# ESP32-S3 register map
Vendor: ESPRESSIF SYSTEMS (SHANGHAI) CO., LTD.; Series: ESP32 S-Series; File version: 22
CPU: Xtensa LX7 r0p0, little endian, no MPU, FPU, 0 interrupt priority bits
Address unit: 32 bits
Registers are 32-bit, read-write, reset 0x0 unless marked. A register's access mark holds for its fields unless they carry their own. Offsets are from the block's base; [hi:lo] are bit positions; {n}, {i} and the like mark numbered series.

## APB_SARADC — SAR (Successive Approximation Register) Analog-to-Digital Converter
Base 0x60040000
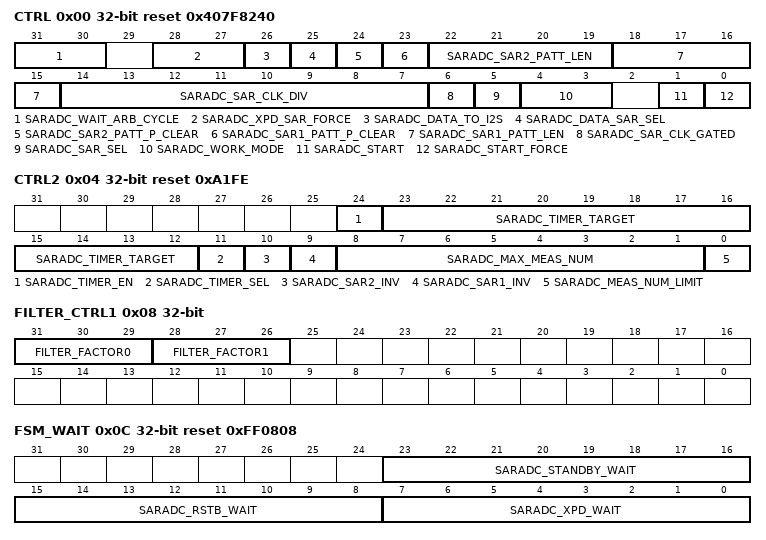
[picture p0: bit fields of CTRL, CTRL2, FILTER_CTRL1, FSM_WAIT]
0x00 CTRL reset 0x407F8240 — configure apb saradc controller
  [31:30] SARADC_WAIT_ARB_CYCLE — wait arbit signal stable after sar_done
  [28:27] SARADC_XPD_SAR_FORCE — force option to xpd sar blocks
  [26] SARADC_DATA_TO_I2S — 1: I2S input data is from SAR ADC (for DMA), 0: I2S input data is from GPIO matrix
  [25] SARADC_DATA_SAR_SEL — 1: sar_sel will be coded by the MSB of the 16-bit output data, in this case the resolution should not be larger than 11 bits.
  [24] SARADC_SAR2_PATT_P_CLEAR — clear the pointer of pattern table for DIG ADC2 CTRL
  [23] SARADC_SAR1_PATT_P_CLEAR — clear the pointer of pattern table for DIG ADC1 CTRL
  [22:19] SARADC_SAR2_PATT_LEN — 0 ~ 15 means length 1 ~ 16
  [18:15] SARADC_SAR1_PATT_LEN — 0 ~ 15 means length 1 ~ 16
  [14:7] SARADC_SAR_CLK_DIV — SAR clock divider
  [6] SARADC_SAR_CLK_GATED — enable SAR CLK gate when saradc idle
  [5] SARADC_SAR_SEL — 0: SAR1, 1: SAR2, only work for single SAR mode
  [4:3] SARADC_WORK_MODE — 0: single mode, 1: double mode, 2: alternate mode
  [1] SARADC_START — start saradc by sw
  [0] SARADC_START_FORCE — enable start saradc by sw
0x04 CTRL2 reset 0xA1FE — configure apb saradc controller
  [24] SARADC_TIMER_EN — to enable saradc timer trigger
  [23:12] SARADC_TIMER_TARGET — to set saradc timer target
  [11] SARADC_TIMER_SEL — 1: select saradc timer 0: i2s_ws trigger
  [10] SARADC_SAR2_INV — 1: data to DIG ADC2 CTRL is inverted, otherwise not
  [9] SARADC_SAR1_INV — 1: data to DIG ADC1 CTRL is inverted, otherwise not
  [8:1] SARADC_MAX_MEAS_NUM — max conversion number
  [0] SARADC_MEAS_NUM_LIMIT — enable apb saradc limit the sample num
0x08 FILTER_CTRL1 — configure saradc filter
  [31:29] FILTER_FACTOR0 — apb saradc factor0
  [28:26] FILTER_FACTOR1 — apb saradc factor1
0x0C FSM_WAIT reset 0xFF0808 — configure apb saradc fsm
  [23:16] SARADC_STANDBY_WAIT — the cycle which saradc controller in standby state
  [15:8] SARADC_RSTB_WAIT — the cycle which saradc controller in rst state
  [7:0] SARADC_XPD_WAIT — the cycle which saradc controller in xpd state
0x10 SAR1_STATUS ro — saradc1 status for debug
  [31:0] SARADC_SAR1_STATUS — saradc1 status
0x14 SAR2_STATUS ro — saradc2 status for debug
  [31:0] SARADC_SAR2_STATUS — saradc2 status
0x18 SAR1_PATT_TAB1 — configure apb saradc pattern table
  [23:0] SARADC_SAR1_PATT_TAB1 — item 0 ~ 3 for pattern table 1 (each item 6bit)
{0x14+4i} SAR1_PATT_TAB{i} (i=2..4) — configure apb saradc pattern table
  [23:0] SARADC_SAR1_PATT_TAB{i} — Item {4i-4} ~ {4i-1} for pattern table 1 (each item 6bit)
0x28 SAR2_PATT_TAB1 — configure apb saradc pattern table
  [23:0] SARADC_SAR2_PATT_TAB1 — item 0 ~ 3 for pattern table 2 (each item 6bit)
{0x24+4i} SAR2_PATT_TAB{i} (i=2..4) — configure apb saradc pattern table
  [23:0] SARADC_SAR2_PATT_TAB{i} — Item {4i-4} ~ {4i-1} for pattern table 2 (each item 6bit)
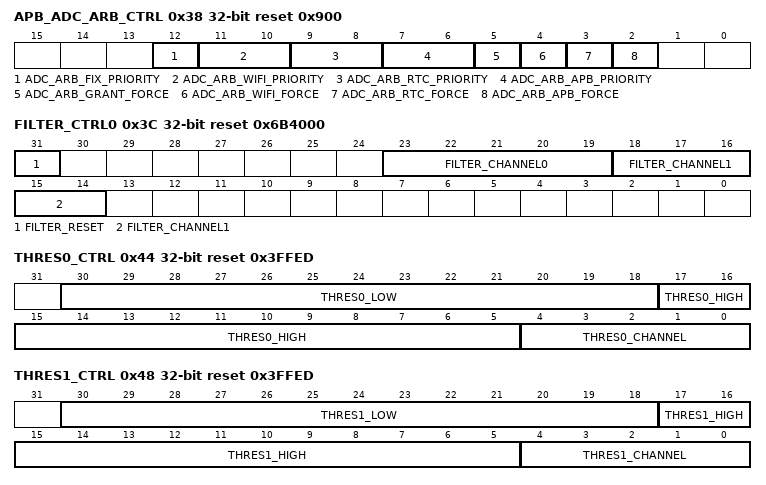
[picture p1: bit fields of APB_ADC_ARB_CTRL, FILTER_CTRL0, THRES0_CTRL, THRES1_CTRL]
0x38 APB_ADC_ARB_CTRL reset 0x900 — configure apb saradc arbit
  [12] ADC_ARB_FIX_PRIORITY — adc2 arbiter uses fixed priority
  [11:10] ADC_ARB_WIFI_PRIORITY — Set adc2 arbiter wifi priority
  [9:8] ADC_ARB_RTC_PRIORITY — Set adc2 arbiter rtc priority
  [7:6] ADC_ARB_APB_PRIORITY — Set adc2 arbiterapb priority
  [5] ADC_ARB_GRANT_FORCE — adc2 arbiter force grant
  [4] ADC_ARB_WIFI_FORCE — adc2 arbiter force to enable wifi controller
  [3] ADC_ARB_RTC_FORCE — adc2 arbiter force to enable rtc controller
  [2] ADC_ARB_APB_FORCE — adc2 arbiter force to enableapb controller
0x3C FILTER_CTRL0 reset 0x6B4000 — configure apb saradc arbit
  [31] FILTER_RESET — enable apb_adc1_filter
  [23:19] FILTER_CHANNEL0 — configure the filter0 channel
  [18:14] FILTER_CHANNEL1 — configure the filter1 channel
0x40 APB_SARADC1_DATA_STATUS ro — get apb saradc sample data
  [16:0] APB_SARADC1_DATA — apbsaradc sample data
0x44 THRES0_CTRL reset 0x3FFED — configure apb saradc thres monitor
  [30:18] THRES0_LOW — thres0 monitor low thres
  [17:5] THRES0_HIGH — thres0 monitor high thres
  [4:0] THRES0_CHANNEL — configure which channel thres0 monitor
0x48 THRES1_CTRL reset 0x3FFED — configure apb saradc thres monitor
  [30:18] THRES1_LOW — thres1 monitor low thres
  [17:5] THRES1_HIGH — thres1 monitor high thres
  [4:0] THRES1_CHANNEL — configure which channel thres0 monitor
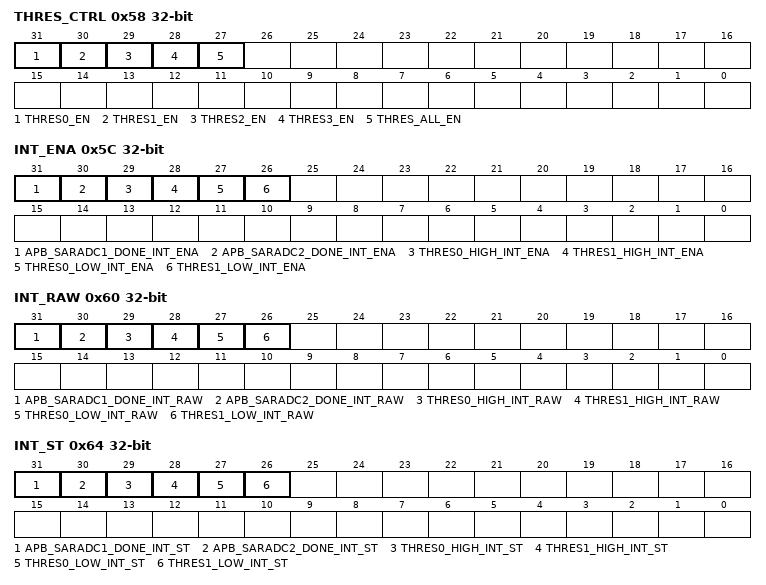
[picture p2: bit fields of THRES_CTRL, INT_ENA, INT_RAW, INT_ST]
0x58 THRES_CTRL — configure thres monitor enable
  [31] THRES0_EN — enable thres0
  [30] THRES1_EN — enable thres1
  [29] THRES2_EN — no public
  [28] THRES3_EN — no public
  [27] THRES_ALL_EN — enable thres0 to monitor all channel
0x5C INT_ENA — enable interrupt
  [31] APB_SARADC1_DONE_INT_ENA — interrupt of sar1 done
  [30] APB_SARADC2_DONE_INT_ENA — interrupt of sar2 done
  [29] THRES0_HIGH_INT_ENA — interrupt of thres0 high
  [28] THRES1_HIGH_INT_ENA — interrupt of thres1 high
  [27] THRES0_LOW_INT_ENA — interrupt of thres0 low
  [26] THRES1_LOW_INT_ENA — interrupt of thres1 low
0x60 INT_RAW ro — raw of interrupt
  [31] APB_SARADC1_DONE_INT_RAW — interrupt of sar1 done
  [30] APB_SARADC2_DONE_INT_RAW — interrupt of sar2 done
  [29] THRES0_HIGH_INT_RAW — interrupt of thres0 high
  [28] THRES1_HIGH_INT_RAW — interrupt of thres1 high
  [27] THRES0_LOW_INT_RAW — interrupt of thres0 low
  [26] THRES1_LOW_INT_RAW — interrupt of thres1 low
0x64 INT_ST ro — state of interrupt
  [31] APB_SARADC1_DONE_INT_ST — interrupt of sar1 done
  [30] APB_SARADC2_DONE_INT_ST — interrupt of sar2 done
  [29] THRES0_HIGH_INT_ST — interrupt of thres0 high
  [28] THRES1_HIGH_INT_ST — interrupt of thres1 high
  [27] THRES0_LOW_INT_ST — interrupt of thres0 low
  [26] THRES1_LOW_INT_ST — interrupt of thres1 low
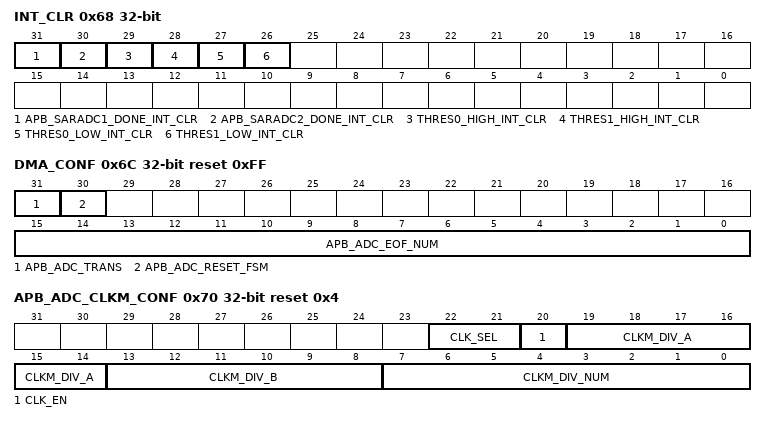
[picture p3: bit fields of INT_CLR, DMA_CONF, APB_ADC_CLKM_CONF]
0x68 INT_CLR wo — clear interrupt
  [31] APB_SARADC1_DONE_INT_CLR — interrupt of sar1 done
  [30] APB_SARADC2_DONE_INT_CLR — interrupt of sar2 done
  [29] THRES0_HIGH_INT_CLR — interrupt of thres0 high
  [28] THRES1_HIGH_INT_CLR — interrupt of thres1 high
  [27] THRES0_LOW_INT_CLR — interrupt of thres0 low
  [26] THRES1_LOW_INT_CLR — interrupt of thres1 low
0x6C DMA_CONF reset 0xFF — configure apb saradc dma
  [31] APB_ADC_TRANS — enable apb_adc use spi_dma
  [30] APB_ADC_RESET_FSM — reset_apb_adc_state
  [15:0] APB_ADC_EOF_NUM — the dma_in_suc_eof gen when sample cnt = spi_eof_num
0x70 APB_ADC_CLKM_CONF reset 0x4 — configure apb saradc clock
  [22:21] CLK_SEL — Set this bit to enable clk_apll
  [20] CLK_EN — no public
  [19:14] CLKM_DIV_A — Fractional clock divider denominator value
  [13:8] CLKM_DIV_B — Fractional clock divider numerator value
  [7:0] CLKM_DIV_NUM — Integral clock divider value
0x78 APB_SARADC2_DATA_STATUS ro — get apb saradc2 sample data
  [16:0] APB_SARADC2_DATA — apb saradc2 sample data
0x3FC APB_CTRL_DATE reset 0x2101180 — version
